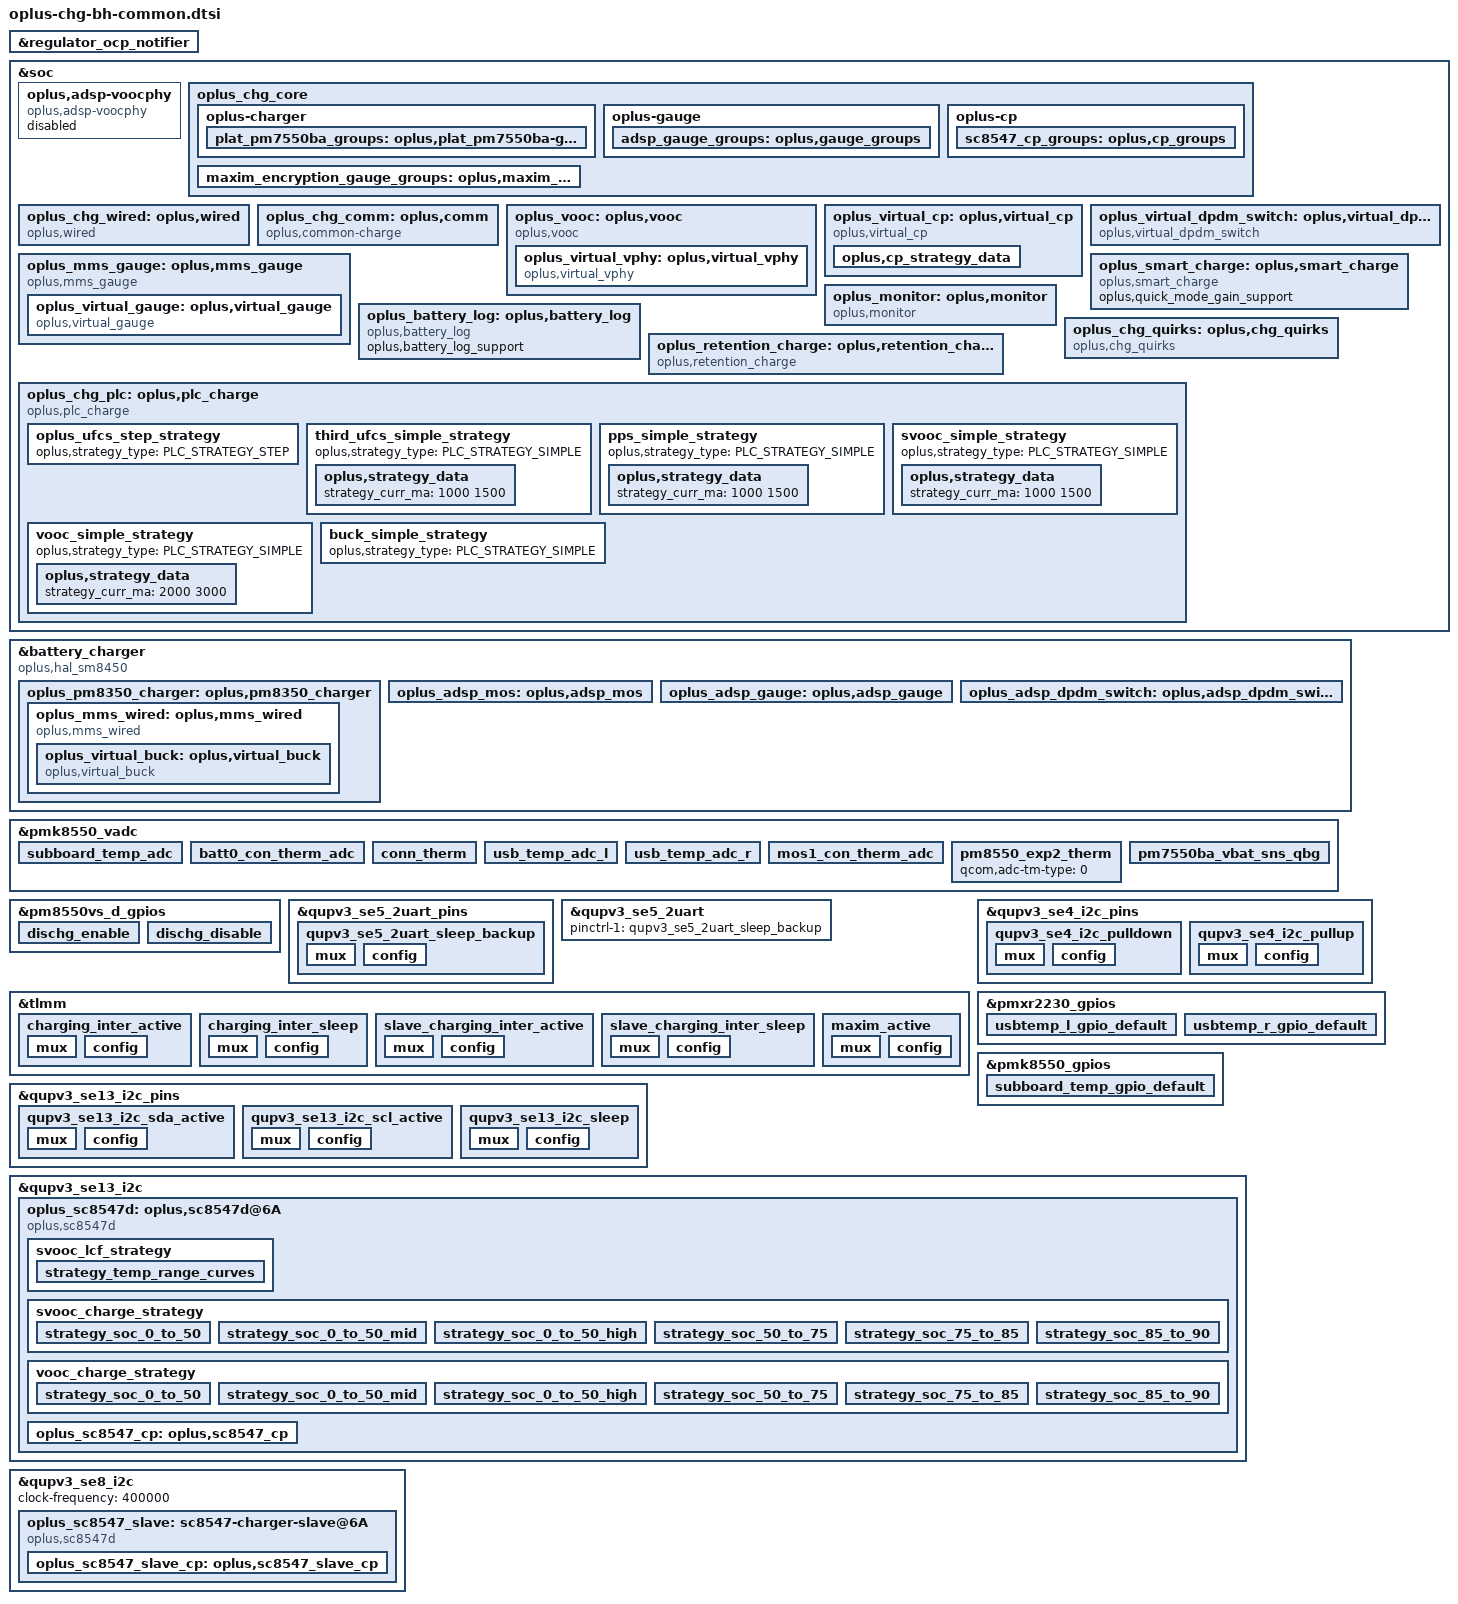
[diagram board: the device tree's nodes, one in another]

&regulator_ocp_notifier {
	periph-1cb-supply = <0>;
	periph-1cc-supply = <0>;
	periph-1cd-supply = <0>;
	periph-4c1-supply = <0>;
	periph-4c3-supply = <0>;
};

&soc {
	oplus,adsp-voocphy {
		status = "disabled";
		compatible = "oplus,adsp-voocphy";
	};

	oplus_chg_core {
		oplus,chg_framework_v2;
		oplus,smart_charging_screenoff;
		oplus,chg_spec_version = <OPLUS_CHG_SPEC_VER_V3P7>;
		oplus,common-charge-icl-support;

		oplus-charger {
			plat_pm7550ba_groups: oplus,plat_pm7550ba-groups {
				functions = <
					OPLUS_IC_FUNC_INIT
					OPLUS_IC_FUNC_EXIT
					OPLUS_IC_FUNC_REG_DUMP
					OPLUS_IC_FUNC_SMT_TEST
					OPLUS_IC_FUNC_BUCK_INPUT_PRESENT
					OPLUS_IC_FUNC_BUCK_INPUT_SUSPEND
					OPLUS_IC_FUNC_BUCK_INPUT_IS_SUSPEND
					OPLUS_IC_FUNC_BUCK_OUTPUT_SUSPEND
					OPLUS_IC_FUNC_BUCK_OUTPUT_IS_SUSPEND
					OPLUS_IC_FUNC_BUCK_GET_CC_ORIENTATION
					OPLUS_IC_FUNC_BUCK_GET_CHARGER_TYPE
					OPLUS_IC_FUNC_BUCK_RERUN_BC12
					OPLUS_IC_FUNC_BUCK_QC_DETECT_ENABLE
					OPLUS_IC_FUNC_BUCK_SHIPMODE_ENABLE
					OPLUS_IC_FUNC_BUCK_SET_QC_CONFIG
					OPLUS_IC_FUNC_BUCK_SET_PD_CONFIG
					OPLUS_IC_FUNC_BACKUP_SOC
					OPLUS_IC_FUNC_GET_SHUTDOWN_SOC
					OPLUS_IC_FUNC_GET_TYPEC_MODE
					OPLUS_IC_FUNC_BUCK_SET_ICL
					OPLUS_IC_FUNC_BUCK_GET_ICL
					OPLUS_IC_FUNC_BUCK_SET_FCC
					OPLUS_IC_FUNC_BUCK_SET_FV
					OPLUS_IC_FUNC_BUCK_SET_ITERM
					OPLUS_IC_FUNC_BUCK_SET_RECHG_VOL
					OPLUS_IC_FUNC_BUCK_GET_INPUT_CURR
					OPLUS_IC_FUNC_BUCK_GET_INPUT_VOL
					OPLUS_IC_FUNC_GET_CHARGER_CYCLE
					OPLUS_IC_FUNC_OTG_BOOST_ENABLE
					OPLUS_IC_FUNC_BUCK_GET_VBUS_COLLAPSE_STATUS
					OPLUS_IC_FUNC_GET_OTG_ENABLE
					OPLUS_IC_FUNC_SET_OTG_SWITCH_STATUS
					OPLUS_IC_FUNC_GET_OTG_SWITCH_STATUS
					OPLUS_IC_FUNC_GET_OTG_ONLINE_STATUS
					OPLUS_IC_FUNC_BUCK_GET_HW_DETECT
					OPLUS_IC_FUNC_VOOCPHY_SET_MATCH_TEMP
					OPLUS_IC_FUNC_IS_OPLUS_SVID
					OPLUS_IC_FUNC_BUCK_GET_USB_BTB_TEMP
					OPLUS_IC_FUNC_BUCK_GET_BATT_BTB_TEMP
					OPLUS_IC_FUNC_SET_TYPEC_MODE
					OPLUS_IC_FUNC_GET_TYPEC_ROLE
					OPLUS_IC_FUNC_BUCK_GET_USB_AICL_ENHANCE
					OPLUS_IC_FUNC_BUCK_SET_AICL_POINT
				>;
				virqs = <
					OPLUS_IC_VIRQ_ERR
					OPLUS_IC_VIRQ_CC_DETECT
					OPLUS_IC_VIRQ_PLUGIN
					OPLUS_IC_VIRQ_CC_CHANGED
					OPLUS_IC_VIRQ_CHG_TYPE_CHANGE
					OPLUS_IC_VIRQ_SVID
					OPLUS_IC_VIRQ_OTG_ENABLE
				>;
			};
		};

		oplus-gauge {
			adsp_gauge_groups: oplus,gauge_groups {
				functions = <
					OPLUS_IC_FUNC_INIT
					OPLUS_IC_FUNC_EXIT
					OPLUS_IC_FUNC_REG_DUMP
					OPLUS_IC_FUNC_SMT_TEST
					OPLUS_IC_FUNC_GAUGE_GET_BATT_VOL
					OPLUS_IC_FUNC_GAUGE_GET_BATT_MAX
					OPLUS_IC_FUNC_GAUGE_GET_BATT_MIN
					OPLUS_IC_FUNC_GAUGE_GET_BATT_CURR
					OPLUS_IC_FUNC_GAUGE_GET_BATT_TEMP
					OPLUS_IC_FUNC_GAUGE_GET_BATT_SOC
					OPLUS_IC_FUNC_GAUGE_GET_BATT_FCC
					OPLUS_IC_FUNC_GAUGE_GET_BATT_CC
					OPLUS_IC_FUNC_GAUGE_GET_BATT_RM
					OPLUS_IC_FUNC_GAUGE_GET_BATT_SOH
					OPLUS_IC_FUNC_GAUGE_GET_BATT_HMAC
					OPLUS_IC_FUNC_GAUGE_SET_BATT_FULL
					OPLUS_IC_FUNC_GAUGE_UPDATE_DOD0
					OPLUS_IC_FUNC_GAUGE_UPDATE_SOC_SMOOTH
					OPLUS_IC_FUNC_GAUGE_GET_CB_STATUS
					OPLUS_IC_FUNC_GAUGE_GET_BATT_NUM
					OPLUS_IC_FUNC_GAUGE_GET_DEVICE_TYPE
					OPLUS_IC_FUNC_GAUGE_GET_DEVICE_TYPE_FOR_VOOC
					OPLUS_IC_FUNC_GAUGE_GET_BATT_FCC
					OPLUS_IC_FUNC_GAUGE_UPDATE
					OPLUS_IC_FUNC_GAUGE_IS_SUSPEND
					OPLUS_IC_FUNC_GAUGE_GET_SUBBOARD_TEMP
					OPLUS_IC_FUNC_GAUGE_GET_BCC_PARMS
					OPLUS_IC_FUNC_GAUGE_GET_DEVICE_TYPE_FOR_BCC
					OPLUS_IC_FUNC_GAUGE_GET_DOD0
					OPLUS_IC_FUNC_GAUGE_GET_DOD0_PASSED_Q
					OPLUS_IC_FUNC_GAUGE_GET_QMAX
					OPLUS_IC_FUNC_GAUGE_GET_QMAX_PASSED_Q
					OPLUS_IC_FUNC_GAUGE_GET_DEC_FG_TYPE
					OPLUS_IC_FUNC_GAUGE_GET_DEC_CV_SOH
					OPLUS_IC_FUNC_GAUGE_SET_VCT
					OPLUS_IC_FUNC_GAUGE_GET_VCT
				>;
				virqs = <
					OPLUS_IC_VIRQ_ERR
					OPLUS_IC_VIRQ_OFFLINE
					OPLUS_IC_VIRQ_RESUME
				>;
			};
		};

		oplus-cp {
			sc8547_cp_groups: oplus,cp_groups {
				functions = <
					OPLUS_IC_FUNC_INIT
					OPLUS_IC_FUNC_EXIT
					OPLUS_IC_FUNC_REG_DUMP
					OPLUS_IC_FUNC_SMT_TEST
					OPLUS_IC_FUNC_CP_ENABLE
					OPLUS_IC_FUNC_CP_HW_INTI
					OPLUS_IC_FUNC_CP_SET_WORK_MODE
					OPLUS_IC_FUNC_CP_GET_WORK_MODE
					OPLUS_IC_FUNC_CP_CHECK_WORK_MODE_SUPPORT
					OPLUS_IC_FUNC_CP_SET_IIN
					OPLUS_IC_FUNC_CP_GET_VIN
					OPLUS_IC_FUNC_CP_GET_IIN
					OPLUS_IC_FUNC_CP_GET_VOUT
					OPLUS_IC_FUNC_CP_GET_IOUT
					OPLUS_IC_FUNC_CP_GET_VAC
					OPLUS_IC_FUNC_CP_SET_WORK_START
					OPLUS_IC_FUNC_CP_GET_WORK_STATUS
					OPLUS_IC_FUNC_CP_SET_ADC_ENABLE
					OPLUS_IC_FUNC_CP_WATCHDOG_ENABLE
					OPLUS_IC_FUNC_CP_SET_UCP_DISABLE
					OPLUS_IC_FUNC_CP_GET_IIN_MAX
					OPLUS_IC_FUNC_CP_WATCHDOG_RESET
				>;
				virqs = <
					OPLUS_IC_VIRQ_ERR
					OPLUS_IC_VIRQ_ONLINE
					OPLUS_IC_VIRQ_OFFLINE
				>;
			};
		};

		maxim_encryption_gauge_groups: oplus,maxim_encryption_gauge_groups {
			functions = <
				OPLUS_IC_FUNC_INIT
				OPLUS_IC_FUNC_EXIT
				OPLUS_IC_FUNC_GAUGE_GET_BATT_AUTH
			>;
			virqs = <
				OPLUS_IC_VIRQ_ERR
			>;
		};
	};

	oplus_chg_wired: oplus,wired {
		compatible = "oplus,wired";
		oplus,vooc-support;

		oplus_spec,vbatt_pdqc_to_9v_thr = <5000>;
		oplus_spec,pd-iclmax-ma = <1500>;
		oplus_spec,qc-iclmax-ma = <1500>;
		oplus_spec,non-standard-ibatmax-ma = <500>;
		oplus_spec,input-power-mw = <
			2500		/* OPLUS_WIRED_CHG_MODE_UNKNOWN */
			2500		/* OPLUS_WIRED_CHG_MODE_SDP */
			7500		/* OPLUS_WIRED_CHG_MODE_CDP */
			10000		/* OPLUS_WIRED_CHG_MODE_DCP */
			30000		/* OPLUS_WIRED_CHG_MODE_VOOC */
			13500		/* OPLUS_WIRED_CHG_MODE_QC */
			13500		/* OPLUS_WIRED_CHG_MODE_PD */
		>;
		oplus_spec,led_on-fccmax-ma = <0 1340 4000 4000 4000 4000 4000 1000 0>;
		oplus_spec,fccmax-ma-lv = <
			0 1705 2200 2200 2200 2200 2200 2200 0	/* OPLUS_WIRED_CHG_MODE_UNKNOWN */
			0 600  600  600  600  600  600  600  0	/* OPLUS_WIRED_CHG_MODE_SDP */
			0 1600 1600 1600 1600 1600 1600 1600 0	/* OPLUS_WIRED_CHG_MODE_CDP */
			0 1705 2200 2200 2200 2200 2200 2200 0	/* OPLUS_WIRED_CHG_MODE_DCP */
			0 1340 3600 3600 3600 3600 3600 2948 0	/* OPLUS_WIRED_CHG_MODE_VOOC */
			0 1705 3300 3300 3300 3300 3300 3300 0	/* OPLUS_WIRED_CHG_MODE_QC */
			0 1705 3300 3300 3300 3300 3300 3300 0	/* OPLUS_WIRED_CHG_MODE_PD */
		>;
		oplus_spec,fccmax-ma-hv = <
			0 1705 2200 2200 2200 2200 2200 2200 0	/* OPLUS_WIRED_CHG_MODE_UNKNOWN */
			0 600  600  600  600  600  600  600  0	/* OPLUS_WIRED_CHG_MODE_SDP */
			0 1600 1600 1600 1600 1600 1600 1600 0	/* OPLUS_WIRED_CHG_MODE_CDP */
			0 1705 2200 2200 2200 2200 2200 2200 0	/* OPLUS_WIRED_CHG_MODE_DCP */
			0 1340 3600 3600 3600 3600 3600 2948 0	/* OPLUS_WIRED_CHG_MODE_VOOC */
			0 1705 3300 3300 3300 3300 3300 3300 0	/* OPLUS_WIRED_CHG_MODE_QC */
			0 1705 3300 3300 3300 3300 3300 3300 0	/* OPLUS_WIRED_CHG_MODE_PD */
		>;

		oplus_spec,cool_down_pdqc_vol_mv = <5000 5000 5000 9000>;
		oplus_spec,cool_down_pdqc_curr_ma = <1200 1500 2000 1500>;
		oplus_spec,cool_down_vooc_curr_ma = <1200 1500 2000 2500 3000 3000>;
		oplus_spec,cool_down_normal_curr_ma = <1200 1500 2000>;

		oplus_spec,vbus_ov_thr_mv = <11000 11000>;
		oplus_spec,vbus_uv_thr_mv = <4300 4300>;

		/* first data is strategy used temp type */
		oplus,vooc_strategy_name = "cgcl";
		oplus,vooc_strategy_data = <OPLUS_STRATEGY_USE_BATT_TEMP
					    0   380 6000 1 0
					    370 410 5000 2 0
					    400 420 4000 3 1
					    410 440 2000 3 2>;
	};

	oplus_chg_comm: oplus,comm {
		compatible = "oplus,common-charge";
		oplus_spec,dec_step = <20>;
		oplus_spec,dec-vol-cc-full-thr = <0 400 600 800 1000 1200>;
		oplus_spec,dec-vol-fv-full-mv = <0 20 20 40 40 40>;
		oplus_spec,batt-them-thr = <(-100) 0 50 120 160 350 450 530>;
		oplus_spec,iterm-ma = <351>;
		oplus_spec,removed_bat_decidegc = <390>; /*-39 degree*/
		oplus_spec,fv-mv = <4490 4490 4490 4490 4490 4490 4470 4130 4130>;
		oplus_spec,sw-fv-mv = <4440 4440 4440 4440 4440 4440 4420 4080 4080>;
		oplus_spec,hw-fv-inc-mv = <0 18 18 18 18 18 18 18 0>;
		oplus_spec,sw-over-fv-mv = <4500 4500 4500 4500 4500 4500 4480 4140 4140>;
		oplus_spec,sw-over-fv-dec-mv = <8>;
		oplus_spec,non-standard-sw-fv-mv = <3930>;
		oplus_spec,non-standard-fv-mv = <3980>;
		oplus_spec,non-standard-hw-fv-inc-mv = <18>;
		oplus_spec,non-standard-sw-over-fv-mv = <3990>;
		oplus_spec,non-standard-vbatdet-mv = <3680>;
		oplus_spec,wired-vbatdet-mv = <0 4190 4290 4390 4390 4390 4370 4030 0>;
		oplus_spec,fcc-gear-thr-mv = <4180>;
		oplus_spec,fcc-gear-shake-mv = <500 500 500 400 300 200 200 200 200>;
		oplus_spec,vbatt-ov-thr-mv = <4600>;

		oplus_spec,full_pre_ffc_judge;
		oplus_spec,full-pre-ffc-mv = <4485>;
		oplus_spec,ffc-temp-thr = <120 210 350 440>;
		oplus_spec,wired-ffc-step-max = <2>;
		oplus_spec,wired-ffc-fv-mv = <4630 4630>;

		oplus_spec,wired-ffc-fv-cutoff-mv = <4560 4525 4504
							4530 4505 4487>;
		oplus_spec,wired-ffc-fcc-ma = <1500 1500 1500
					       1500  1000  1000>;
		oplus_spec,wired-ffc-fcc-cutoff-ma = <1300 1300 1300
						      900 900 900>;

		oplus_spec,vbat_uv_thr_mv = <3300>;
		oplus_spec,vbat_charging_uv_thr_mv = <3200>;

		/*If use subboard NTC as battery temp, config it as 20, otherwise 0 */
		oplus_spec,tbatt_power_off_cali_temp = <0>;
		oplus,vooc_show_ui_soc_decimal;
		oplus_spec,poweroff_high_batt_temp = <720>;
		oplus_spec,poweroff_emergency_batt_temp = <770>;
		oplus,ui_soc_decimal_speedmin = <20>;

		oplus,gauge_stuck_jump_support;
		oplus,gauge_stuck_threshold = <15>;
		oplus,gauge_stuck_time = <50>;

		oplus,smooth_switch;
		oplus,reserve_chg_soc = <2>;
	};

	oplus_vooc: oplus,vooc {
		compatible = "oplus,vooc";
		oplus,vooc_ic = <&oplus_virtual_vphy>;

		oplus_spec,vooc_soc_range = <50 75 85>;
		oplus_spec,vooc_temp_range = <50 120 180 350 450>;

		oplus,vooc_data_width = <7>;
		oplus,vooc_curr_max = <CP_CURR_LIMIT_7BIT_15_0A>;  /* 80W: 11V 7.3A(IBUS *2) */
		oplus,vooc_project = <7>;  /* 80W, 11V 7.3A */
		oplus,vooc_curr_table_type = <VOOC_CP_CURR_TABLE>;
		oplus,vooc_power_max_w = <80>;
		oplus,voocphy_support = <3>; /* AP_DUAL_CP_VOOCPHY */
		oplus,support_fake_vooc_check;
		oplus,subboard_ntc_abnormal_current = <4000>;

		oplus,abnormal_adapter_current = <CP_CURR_LIMIT_7BIT_15_0A CP_CURR_LIMIT_7BIT_15_0A
						CP_CURR_LIMIT_7BIT_10_0A CP_CURR_LIMIT_7BIT_10_0A
						CP_CURR_LIMIT_7BIT_8_0A CP_CURR_LIMIT_7BIT_8_0A
						CP_CURR_LIMIT_7BIT_6_0A CP_CURR_LIMIT_7BIT_6_0A
						CP_CURR_LIMIT_7BIT_4_0A CP_CURR_LIMIT_7BIT_4_0A>;

		oplus,abnormal_over_80w_adapter_current = <CP_CURR_LIMIT_7BIT_15_0A CP_CURR_LIMIT_7BIT_15_0A
						CP_CURR_LIMIT_7BIT_14_0A CP_CURR_LIMIT_7BIT_14_0A
						CP_CURR_LIMIT_7BIT_12_0A CP_CURR_LIMIT_7BIT_12_0A
						CP_CURR_LIMIT_7BIT_10_0A CP_CURR_LIMIT_7BIT_10_0A
						CP_CURR_LIMIT_7BIT_8_0A  CP_CURR_LIMIT_7BIT_8_0A
						CP_CURR_LIMIT_7BIT_6_0A  CP_CURR_LIMIT_7BIT_6_0A
						CP_CURR_LIMIT_7BIT_4_0A CP_CURR_LIMIT_7BIT_4_0A>;

		/* first data is strategy used temp type */
		oplus,general_strategy_name = "cgcl";
		oplus,general_strategy_data = < OPLUS_STRATEGY_USE_SHELL_TEMP
						0   370 CP_CURR_LIMIT_7BIT_15_0A 1 0
						360 390 CP_CURR_LIMIT_7BIT_10_0A 2 0
						380 410 CP_CURR_LIMIT_7BIT_8_0A  3 1
						400 420 CP_CURR_LIMIT_7BIT_6_0A  4 2
						410 440 CP_CURR_LIMIT_7BIT_4_0A  4 3>;
		oplus,plc_strategy-data = <&buck_simple_strategy &svooc_simple_strategy &vooc_simple_strategy>;
		oplus,plc_strategy-names = "default", "svooc", "vooc";
		oplus_virtual_vphy: oplus,virtual_vphy {
			compatible = "oplus,virtual_vphy";
			oplus,vphy_ic = <&oplus_sc8547d>;
			oplus,dpdm_switch_ic = <&oplus_virtual_dpdm_switch>;

			oplus,ic_type = <OPLUS_CHG_IC_VIRTUAL_VPHY>;
			oplus,ic_index = <0>;
		};
	};

	oplus_virtual_cp: oplus,virtual_cp {
		compatible = "oplus,virtual_cp";

		oplus,ic_type = <OPLUS_CHG_IC_VIRTUAL_CP>;
		oplus,ic_index = <0>;

		oplus,cp_ic = <&oplus_sc8547_cp &oplus_sc8547_slave_cp>;
		oplus,input_curr_max_ma = <4000 4000>;

		oplus,cp_ic_connect = <OPLUS_CHG_IC_CONNECT_PARALLEL>;
		oplus,main_cp = <0>;

		oplus,reg_proc_node;
		oplus,cp_strategy = <CP_STRAT_OPEN_BY_CURR>;
		oplus,cp_strategy_data {
			oplus,cp_open_curr_thr_ma = <0 1900>;
			oplus,cp_close_curr_thr_ma = <0 1600>;
		};
	};

	oplus_virtual_dpdm_switch: oplus,virtual_dpdm_switch {
		compatible = "oplus,virtual_dpdm_switch";
		oplus,ic_type = <OPLUS_CHG_IC_MISC>;
		oplus,ic_index = <0>;
		oplus,use_audio_switch;
	};

	oplus_mms_gauge: oplus,mms_gauge {
		compatible = "oplus,mms_gauge";
		oplus,gauge_ic = <&oplus_virtual_gauge>;
		oplus,voocphy_ic = <&oplus_virtual_vphy>;
		oplus,topic-update-interval = <5000>;
		oplus,support_subboard_ntc;

		oplus_virtual_gauge: oplus,virtual_gauge {
			compatible = "oplus,virtual_gauge";
			oplus,gauge_ic = <&oplus_adsp_gauge &maxim_encryption_gauge>;
			oplus,gauge_ic_index = <0 1>;
			oplus,gauge_ic_func_group =  <&adsp_gauge_groups &maxim_encryption_gauge_groups>;
			oplus,batt_capacity_mah = <7000>;
			oplus,ic_type = <OPLUS_CHG_IC_VIRTUAL_GAUGE>;
			oplus,ic_index = <0>;
		};
	};

	oplus_smart_charge: oplus,smart_charge {
		compatible = "oplus,smart_charge";
		oplus,quick_mode_gain_support;
	};


	oplus_battery_log: oplus,battery_log {
		compatible = "oplus,battery_log";
		oplus,battery_log_support;
	};

	oplus_monitor: oplus,monitor {
		compatible = "oplus,monitor";
		oplus,topic-update-interval = <60000>;
		track,fast_chg_break_t_thd = <1400>;
		track,general_chg_break_t_thd = <300>;
		track,voocphy_type = <2>;
		track,wired_max_power = <80000>;
		track,wired_fast_chg_scheme = <1>;
	};

	oplus_chg_quirks: oplus,chg_quirks {
		compatible = "oplus,chg_quirks";
	};
	oplus_retention_charge: oplus,retention_charge {
		compatible = "oplus,retention_charge";
		oplus,topic-update-interval = <5000>;
		oplus,support_retention_name = "oplus_retention_quirks";
	};
};

&soc {
	oplus_chg_plc: oplus,plc_charge {
		compatible = "oplus,plc_charge";
		oplus,plc_soc = <90>;
		oplus,plc_strategy-data = <&buck_simple_strategy>;
		oplus,plc_strategy-names = "default";

		oplus_ufcs_step_strategy: oplus_ufcs_step_strategy {
			oplus,strategy_type = <PLC_STRATEGY_STEP>;
		};

		third_ufcs_simple_strategy: third_ufcs_simple_strategy {
			oplus,strategy_type = <PLC_STRATEGY_SIMPLE>;
			oplus,strategy_data {
				strategy_curr_ma = <1000 1500>;
			};
		};

		pps_simple_strategy: pps_simple_strategy {
			oplus,strategy_type = <PLC_STRATEGY_SIMPLE>;
			oplus,strategy_data {
				strategy_curr_ma = <1000 1500>;
			};
		};

		svooc_simple_strategy: svooc_simple_strategy {
			oplus,strategy_type = <PLC_STRATEGY_SIMPLE>;
			oplus,strategy_data {
				strategy_curr_ma = <1000 1500>;
			};
		};

		vooc_simple_strategy: vooc_simple_strategy {
			oplus,strategy_type = <PLC_STRATEGY_SIMPLE>;
			oplus,strategy_data {
				strategy_curr_ma = <2000 3000>;
			};
		};


		buck_simple_strategy: buck_simple_strategy {
			oplus,strategy_type = <PLC_STRATEGY_SIMPLE>;
		};
	};
};

&battery_charger {
	compatible = "oplus,hal_sm8450";

	qcom,pmic_ftm_vph = "/sys/bus/spmi/drivers/pmic-spmi/0-00/c42d000.qcom,spmi:qcom,pmk8550@0:vadc@9000/iio:device0/in_voltage_pm7550ba_vph_pwr_input";
	qcom,pmic_ftm_vbat = "/sys/bus/spmi/drivers/pmic-spmi/0-00/c42d000.qcom,spmi:qcom,pmk8550@0:vadc@9000/iio:device0/in_voltage_pm7550ba_vbat_sns_qbg_input";

	pinctrl-names = "subboard_temp_gpio_default";
	pinctrl-0 = <&subboard_temp_gpio_default>;

	//oplus,voocphy_bidirect_cp_support;
	oplus,chg_ops = "plat-pmic";
	oplus,otg_boost_src = <0>; /* 0:plat_pmic 1:external */
	oplus,batt_num = <1>;
	oplus,otg_scheme = <0>; /* 0:cid 1:ccdetect_gpio 2:switch */
	oplus,usb_aicl_enhance;

	/* QCOM QBG full param, depend on adapter type and temp_region */
	oplus,batt_full_method_new;
	oplus,batt_full_temp = <(-100) 120 210 440>;
	oplus,batt_full_para = <1351 1351 1351 1351      /* normal pd qc */
				1351 2751 2951 1351      /* svooc */
				1351 2751 2951 1351      /* oplus ufcs */
				1351 2751 2751 1351      /* oplus pps */
				1351 1351 1351 1351      /* third ufcs */
				1351 1351 1351 1351      /* third pps */
				1351 1351 1451 1351>;    /* ffc */

	oplus,ic_type = <OPLUS_CHG_IC_BUCK>;
	oplus,ic_index = <0>;
	io-channels = <&pmk8550_vadc PMK8550_ADC5_GEN3_AMUX_THM3_GPIO2_100K_PU>,
		      <&pmk8550_vadc PMK8550_ADC5_GEN3_AMUX_THM2_GPIO1_100K_PU>,
		      <&pmk8550_vadc PM7550BA_ADC5_GEN3_AMUX_THM6_GPIO6_100K_PU>,
		      <&pmk8550_vadc PM7550BA_ADC5_GEN3_AMUX_THM4_USB_THERM_100K_PU>;

	io-channel-names = "mos1_con_therm_adc",
			   "subboard_temp_adc",
			   "batt0_con_therm_adc",
			   "conn_therm";

	oplus_pm8350_charger: oplus,pm8350_charger {
		oplus,ic_type = <OPLUS_CHG_IC_BUCK>;
		oplus,ic_index = <0>;

		oplus_mms_wired: oplus,mms_wired {
			compatible = "oplus,mms_wired";
			oplus,buck_ic = <&oplus_virtual_buck>;
			oplus,voocphy_ic = <&oplus_virtual_vphy>;
			oplus,usbtemp_batttemp_gap = <10>;
			oplus,adc_info_name = "855";
			oplus,topic-update-interval = <5000>;

			high-temp-scheme;
			oplus,support_usbtemp_protect_v2;
			oplus_spec,usbtemp_batt_temp_low = <50>;
			oplus_spec,usbtemp_batt_temp_high = <50>;
			oplus_spec,usbtemp_batt_temp_over_hot = <60>;
			oplus_spec,usbtemp_ntc_temp_low = <57>;
			oplus_spec,usbtemp_ntc_temp_high = <69>;
			oplus_spec,usbtemp_temp_gap_low_with_batt_temp = <7>;
			oplus_spec,usbtemp_temp_gap_with_batt_temp_in_over_hot = <15>;
			oplus_spec,usbtemp_temp_gap_high_with_batt_temp = <12>;
			oplus_spec,usbtemp_temp_gap_low_without_batt_temp = <12>;
			oplus_spec,usbtemp_temp_gap_high_without_batt_temp = <24>;
			oplus_spec,usbtemp_rise_fast_temp_low = <3>;
			oplus_spec,usbtemp_rise_fast_temp_high = <3>;
			oplus_spec,usbtemp_rise_fast_temp_count_low = <30>;
			oplus_spec,usbtemp_rise_fast_temp_count_high = <20>;
			oplus_spec,usbtemp_cool_down_ntc_low = <54>;
			oplus_spec,usbtemp_cool_down_ntc_high = <65>;
			oplus_spec,usbtemp_cool_down_gap_low = <12>;
			oplus_spec,usbtemp_cool_down_gap_high = <20>;
			oplus_spec,usbtemp_cool_down_recover_ntc_low = <48>;
			oplus_spec,usbtemp_cool_down_recover_ntc_high = <60>;
			oplus_spec,usbtemp_cool_down_recover_gap_low = <6>;
			oplus_spec,usbtemp_cool_down_recover_gap_high = <15>;

		oplus_virtual_buck: oplus,virtual_buck {
			compatible = "oplus,virtual_buck";
			oplus,buck_ic = <&oplus_pm8350_charger>;
			oplus,buck_ic_index = <0>;
			oplus,buck_ic_connect = <OPLUS_CHG_IC_CONNECT_PARALLEL>;
			oplus,main_charger = <0>;
			oplus,buck_ic_current_ratio = <100>;
			oplus,buck_ic_func_group = <&plat_pm7550ba_groups>;

			oplus,ic_type = <OPLUS_CHG_IC_VIRTUAL_BUCK>;
			oplus,ic_index = <0>;

			oplus,uart_tx-gpio = <&tlmm 22 0x00>;
			oplus,uart_rx-gpio = <&tlmm 23 0x00>;

			oplus,dischg-gpio = <&pm8550vs_d_gpios 4 0x00>;
			//oplus,ship-gpio = <&tlmm 146 0x00>;
			pinctrl-names = "usbtemp_l_gpio_default", "usbtemp_r_gpio_default", /* TODO */
					"dischg_enable", "dischg_disable";
			pinctrl-0 = <&usbtemp_l_gpio_default>;
			pinctrl-1 = <&usbtemp_r_gpio_default>;
			pinctrl-2 = <&dischg_enable>;
			pinctrl-3 = <&dischg_disable>;

			io-channels = <&pmk8550_vadc PMXR2230_ADC5_GEN3_AMUX1_GPIO3_100K_PU>,
				      <&pmk8550_vadc PMXR2230_ADC5_GEN3_AMUX2_GPIO4_100K_PU>;
			io-channel-names = "usb_temp_adc_l",
					   "usb_temp_adc_r";
			};
		};
	};

	oplus_adsp_mos: oplus,adsp_mos {
		oplus,ic_type = <OPLUS_CHG_IC_CP>;
		oplus,ic_index = <0>;
	};

	oplus_adsp_gauge: oplus,adsp_gauge {
		oplus,ic_type = <OPLUS_CHG_IC_GAUGE>;
		oplus,ic_index = <0>;
	};

	oplus_adsp_dpdm_switch: oplus,adsp_dpdm_switch {
		oplus,ic_type = <OPLUS_CHG_IC_MISC>;
		oplus,ic_index = <0>;
	};
};

&pmk8550_vadc {
	subboard_temp_adc {
		reg = <PMK8550_ADC5_GEN3_AMUX_THM2_GPIO1_100K_PU>;
		label = "subboard_temp_adc";
		qcom,pre-scaling = <1 1>;
		qcom,ratiometric;
		qcom,hw-settle-time = <200>;
		qcom,scale-fn-type = <OPLUS_ADC_SCALE_HW_CALIB_DEFAULT>;
	};

	batt0_con_therm_adc {
		reg = <PM7550BA_ADC5_GEN3_AMUX_THM6_GPIO6_100K_PU>;
                label = "batt0_con_therm_adc";
                qcom,pre-scaling = <1 1>;
                qcom,ratiometric;
                qcom,hw-settle-time = <200>;
                qcom,scale-fn-type = <OPLUS_ADC_SCALE_HW_CALIB_DEFAULT>;
	};

	conn_therm {
		reg = <PM7550BA_ADC5_GEN3_AMUX_THM4_USB_THERM_100K_PU>;
                label = "conn_therm";
                qcom,pre-scaling = <1 1>;
                qcom,ratiometric;
                qcom,hw-settle-time = <200>;
                qcom,scale-fn-type = <OPLUS_ADC_SCALE_HW_CALIB_DEFAULT>;
	};

	usb_temp_adc_l {
		reg = <PMXR2230_ADC5_GEN3_AMUX1_GPIO3_100K_PU>;
                label = "usb_temp_adc_l";
                qcom,pre-scaling = <1 1>;
                qcom,ratiometric;
                qcom,hw-settle-time = <200>;
                qcom,scale-fn-type = <OPLUS_ADC_SCALE_HW_CALIB_DEFAULT>;
	};

	usb_temp_adc_r{
		reg = <PMXR2230_ADC5_GEN3_AMUX2_GPIO4_100K_PU>;
                label = "usb_supplementary_temp_adc ";
                qcom,pre-scaling = <1 1>;
                qcom,ratiometric;
                qcom,hw-settle-time = <200>;
                qcom,scale-fn-type = <OPLUS_ADC_SCALE_HW_CALIB_DEFAULT>;
	};

	/* TODO: the mos themperature is used by which? */
	mos1_con_therm_adc {
		reg = <PMK8550_ADC5_GEN3_AMUX_THM3_GPIO2_100K_PU>;
                label = "mos1_con_therm_adc";
                qcom,pre-scaling = <1 1>;
                qcom,ratiometric;
                qcom,hw-settle-time = <200>;
                qcom,scale-fn-type = <OPLUS_ADC_SCALE_HW_CALIB_DEFAULT>;
	};

	/* disable the pm8550_exp2_therm to fix the usb_temp_adc init failed! */
	pm8550_exp2_therm {
		qcom,adc-tm-type = <0>;
	};

	pm7550ba_vbat_sns_qbg {
		reg = <PM7550BA_ADC5_GEN3_VBAT_SNS_QBG>;
		label = "pm7550ba_vbat_sns_qbg";
		qcom,pre-scaling = <1 3>;
	};
};

&pm8550vs_d_gpios {
	dischg_enable: dischg_enable {
		pins = "gpio4";
		function = "normal";
		bias-disable;
		power-source = <0>;
		output-high;
		qcom,drive-strength = <2>;
	};

	dischg_disable: dischg_disable {
		pins = "gpio4";
		function = "normal";
		bias-disable;
		power-source = <0>;
		output-low;
		qcom,drive-strength = <2>;
	};
};

&qupv3_se5_2uart_pins {
	qupv3_se5_2uart_sleep_backup:qupv3_se5_2uart_sleep_backup {
 		mux {
			pins = "gpio22", "gpio23";
			function = "gpio";
		};

		config {
			pins = "gpio22", "gpio23";
			drive-strength = <2>;
			bias-disable;
			input-enable;
		};
	};
};

&qupv3_se5_2uart {
	pinctrl-1 = <&qupv3_se5_2uart_sleep_backup>;
	status = "ok";
};

&tlmm {
	charging_inter_active: charging_inter_active {
		mux {
			pins = "gpio51";
			function = "gpio";
		};
		config {
			pins = "gpio51";
			bias-pull-up; /* NO pull */
			drive-strength = <2>; /* 2 MA */
			input-enable;
		};
	};

	charging_inter_sleep: charging_inter_sleep {
		mux {
			pins = "gpio51"; /* sc8547d_INT*/
			function = "gpio";
		};
		config {
			pins = "gpio51";
			bias-pull-up;
			drive-strength = <2>; /* 2 MA */
			input-enable;
		};
	};

	slave_charging_inter_active: slave_charging_inter_active {
		mux {
			pins = "gpio128";
			function = "gpio";
		};
		config {
			pins = "gpio128";
			bias-pull-up;
			drive-strength = <2>;
			input-enable;
		};
	};

	slave_charging_inter_sleep: slave_charging_inter_sleep {
		mux {
			pins = "gpio128";
			function = "gpio";
		};
		config {
			pins = "gpio128";
			bias-pull-up;
			drive-strength = <2>;
			input-enable;
		};
	};

	maxim_active: maxim_active {
		mux {
			pins = "gpio146";
			function = "gpio";
		};

		config {
			pins = "gpio146";
			bias-pull-up;
			drive-strength = <16>;
		};
	};
};

&qupv3_se4_i2c_pins {
	qupv3_se4_i2c_pulldown: qupv3_se4_i2c_pulldown {
		mux {
			pins = "gpio16", "gpio17";
			function = "gpio";
		};

		config {
			pins = "gpio16", "gpio17";
			drive-strength = <2>;
			bias-pull-down;
			output-low;
		};
	};

	qupv3_se4_i2c_pullup: qupv3_se4_i2c_pullup {
		mux {
			pins = "gpio16", "gpio17";
			function = "gpio";
		};

		config {
			pins = "gpio16", "gpio17";
			drive-strength = <2>;
			bias-pull-up;
			input-enable;
		};
	};
};

&qupv3_se13_i2c_pins {
	qupv3_se13_i2c_sda_active: qupv3_se13_i2c_sda_active {
		mux {
			pins = "gpio52";
			function = "qup1_se5_l0";
		};

		config {
			pins = "gpio52";
			drive-strength = <2>;
			bias-pull-up;
			qcom,i2c_pull; /* 2.2k Pull up */
		};
	};

	qupv3_se13_i2c_scl_active: qupv3_se13_i2c_scl_active {
		mux {
			pins = "gpio53";
			function = "qup1_se5_l1";
		};

		config {
			pins = "gpio53";
			drive-strength = <2>;
			bias-pull-up;
			qcom,i2c_pull; /* 2.2k Pull up */
		};
	};

	qupv3_se13_i2c_sleep: qupv3_se13_i2c_sleep {
		mux {
			pins = "gpio52", "gpio53";
			function = "gpio";
		};

		config {
			pins = "gpio52", "gpio53";
			drive-strength = <2>;
			bias-pull-up;
			qcom,i2c_pull; /* 2.2k Pull up */
		};
	};
};

&pmxr2230_gpios {
	usbtemp_l_gpio_default: usbtemp_l_gpio_default {
		pins = "gpio3"; //GPIO 3
		function = "normal"; //normal
		bias-high-impedance; //DISABLE GPIO3 for ADC
		bias-disable;
	};

	usbtemp_r_gpio_default: usbtemp_r_gpio_default {
		pins = "gpio4"; //GPIO 4
		function = "normal"; //normal
		bias-high-impedance; //DISABLE GPIO4 for ADC
		bias-disable;
	};
};

&pmk8550_gpios {
	subboard_temp_gpio_default: subboard_temp_gpio_default {
		pins = "gpio1"; /* GPIO 1 */
		function = "normal"; /* normal */
		bias-high-impedance; /* DISABLE GPIO1 for ADC*/
	};
};

&qupv3_se13_i2c {
	status = "okay";
	qcom,clk-freq-out = <400000>;
	qcom,request-cpu-qos;
	pinctrl-names = "default", "sleep";
	pinctrl-0 = <&qupv3_se13_i2c_sda_active>, <&qupv3_se13_i2c_scl_active>;
	pinctrl-1 = <&qupv3_se13_i2c_sleep>;

	oplus_sc8547d: oplus,sc8547d@6A {
		status = "okay";
		compatible = "oplus,sc8547d";
		reg = <0x6A>;

		ocp_reg = <0xe>;
		ovp_reg = <0x36>;
		vbus_ovp_reg = /bits/ 8 <0x5A>;

		oplus,use_vooc_phy;
		oplus,use_ufcs_phy;
		oplus,vac_support;
		oplus,always_otg_en;
		oplus,irq_gpio = <&tlmm 51 0x00>;
		pinctrl-names = "charging_inter_active", "charging_inter_sleep";
		pinctrl-0 = <&charging_inter_active>;
		pinctrl-1 = <&charging_inter_sleep>;

		oplus,ic_type = <OPLUS_CHG_IC_VPHY>;
		oplus,ic_index = <0>;
		oplus,vooc-version = <VOOC_VERSION_5_0>;

		oplus_spec,vooc_bad_volt = <3450 3400 3350 3300>;
		oplus_spec,vooc_bad_volt_suspend = <3450 3400 3350 3300>;
		oplus_spec,vooc_bad_volt_check_head_mask = /bits/ 8 <0x3>; /* VOOC 2.0/VOOC3.0 */
		oplus_spec,ap_control_allow;

		oplus_spec,voocphy_dual_cp_support;
		oplus_spec,slave_cp_enable_thr = <1400>;		//2000-100mA
		oplus_spec,slave_cp_disable_thr_high = <1100>;//1500+100mA
		oplus_spec,impedance_calculation_newmethod;
		oplus_spec,svooc_circuit_r_l = <0xa>;
		oplus_spec,svooc_circuit_r_h = <0x1>;
		oplus_spec,voocphy_current_default = <73>;

		oplus_spec,svooc_cool_down_current_limit = <146 20 20 24 30 34 40 44 50 54 60 64 70 74 80 90 100 110 146>;
		oplus_spec,vooc_cool_down_current_limit = <73 20 20 24 30 34 40 44 50 54 73>;

		oplus_spec,vooc_multistep_initial_batt_temp = <1000>;
		oplus_spec,vooc_little_cool_temp = <160>;
		oplus_spec,vooc_little_cool_high_temp = <210>;
		oplus_spec,vooc_cool_temp = <120>;
		oplus_spec,vooc_little_cold_temp = <50>;
		oplus_spec,vooc_normal_low_temp = <350>;
		oplus_spec,vooc_strategy_normal_current = <146>;
		oplus_spec,vooc_normal_to_little_cool_current = <100>;
		oplus_spec,vooc_over_high_temp = <510>;
		oplus_spec,vooc_low_temp = <0>;

		oplus_spec,vooc_high_temp = <500>;
		oplus_spec,vooc_low_soc = <0>;
		oplus_spec,vooc_high_soc = <90>;
		oplus_spec,vooc_normal_high_temp = <440>;
		oplus_spec,vooc_warm_vol_thr = <4000>;
		oplus_spec,vooc_warm_soc_thr = <55>;

		oplus_spec,vooc_strategy1_batt_high_temp0 = <385>;
		oplus_spec,vooc_strategy1_batt_high_temp1 = <395>;
		oplus_spec,vooc_strategy1_batt_high_temp2 = <420>;
		oplus_spec,vooc_strategy1_batt_low_temp2 = <410>;
		oplus_spec,vooc_strategy1_batt_low_temp1 = <385>;
		oplus_spec,vooc_strategy1_batt_low_temp0 = <375>;

		oplus_spec,vooc_strategy1_high_current0 = <80>;
		oplus_spec,vooc_strategy1_high_current1 = <60>;
		oplus_spec,vooc_strategy1_high_current2 = <40>;
		oplus_spec,vooc_strategy1_low_current2 = <60>;
		oplus_spec,vooc_strategy1_low_current1 = <80>;
		oplus_spec,vooc_strategy1_low_current0 = <146>;

		oplus_spec,vooc_strategy1_high_current0_vooc = <59>;
		oplus_spec,vooc_strategy1_high_current1_vooc = <59>;
		oplus_spec,vooc_strategy1_high_current2_vooc = <40>;
		oplus_spec,vooc_strategy1_low_current2_vooc = <59>;
		oplus_spec,vooc_strategy1_low_current1_vooc = <59>;
		oplus_spec,vooc_strategy1_low_current0_vooc = <59>;

		oplus_spec,voocphy_req_freq = <1804800 2400000 2400000 2630400>;
		oplus_spec,voocphy_freq_mincore = <1804800>;
		oplus_spec,voocphy_freq_midcore = <2400000>;
		oplus_spec,voocphy_freq_maxcore = <2630400>;
		oplus_spec,voocphy_current_change_timeout = <100>;
		oplus_spec,copycat_vooc_support;
		oplus_spec,copycat_vooc_accuracy_value = <105>;

		oplus_spec,fastchg_timeout_time_init = <175370>;
		oplus_spec,voocphy_ibat_over_current = <16000>;
		oplus_spec,voocphy_svooc_cp_max_ibus = <4200>;
		oplus_spec,voocphy_vooc_cp_max_ibus = <4200>;
		oplus_spec,voocphy_cp_max_ibus = <4500>;

		oplus_spec,vooc_little_cold_full_voltage = <4570>;
		oplus_spec,vooc_cool_full_voltage = <4570>;
		oplus_spec,vooc_little_cool_full_voltage = <4570>;
		oplus_spec,vooc_little_cool_high_full_voltage = <4570>;
		oplus_spec,vooc_warm_full_voltage = <4130>;
		oplus_spec,vooc_1time_full_voltage = <4585>;
		oplus_spec,vooc_ntime_full_voltage = <4575>;
		oplus_spec,full_voltage = < /* vol_1time vol_ntime */
					4580 4570 /* 0 ~ 5 */
					4580 4570 /* 5 ~ 12 */
					4580 4570 /* 12 ~ 16 */
					4580 4570 /* 16 ~ 20 */
					4585 4575 /* 20 ~ 35 */
					4580 4570 /* 35 ~ 44 */
					4140 4130 /* 44 ~ 51 */
					>;

		oplus_spec,low_curr_full_t1 = <120>;
		oplus_spec,low_curr_full_t2 = <350>;
		oplus_spec,low_curr_full_t3 = <430>;
		svooc_batt_sys_curve = <0 1 0 1 0 0 0	// 4000mA
					1 1 1 1 0 0 0	// 4604mV
					0 0 1 1 0 1 0	// 2600mA
					1 1 1 1 0 0 0	// 4604mV
					0 0 0 1 0 1 1	// 1100mA
					1 1 1 1 0 0 0>;	// 4604mV

		vooc_batt_sys_curve =  <0 1 0 1 0 0 0	// 4000mA
					1 1 1 1 0 0 0	// 4604mV
					0 0 1 1 0 1 0	// 2600mA
					1 1 1 1 0 0 0	// 4604mV
					0 0 0 1 0 1 1	// 1100mA
					1 1 1 1 0 0 0>;	// 4604mV

		oplus_spec,soc_range = <0 20 35 55 75 85 90>;

		svooc_lcf_strategy {
			oplus,temp_type = <OPLUS_STRATEGY_USE_SHELL_TEMP>;
			oplus,temp_range = <0 50 120 160 210 380 440>;

			strategy_temp_range_curves {
				strategy_temp_range_t0 =	<1250 4570 0
								 1200 4560 0
								 1150 4550 0
								 1100 4540 0
								 1050 4530 1>;
				strategy_temp_range_t1 =	<1350 4570 0
								 1300 4565 0
								 1250 4550 0
								 1150 4540 0
								 1050 4530 1>;
				strategy_temp_range_t2 =	<2050 4570 0
								 2000 4565 0
								 1900 4550 0
								 1800 4540 0
								 1650 4530 1>;
				strategy_temp_range_t3 =	<2600 4560 0
								 2400 4550 0
								 2000 4542 0
								 1800 4530 0
								 1500 4510 1>;
				strategy_temp_range_t4 =	<2600 4560 0
								 2400 4550 0
								 2000 4542 0
								 1800 4530 0
								 1500 4510 1>;
				strategy_temp_range_t5 =	<3100 4550 0
								 2800 4536 0
								 2400 4524 0
								 2000 4509 0
								 1500 4492 1>;
			};
		};

		svooc_charge_strategy {
			strategy_soc_0_to_50 {  /* 0 ~ 20 */
				strategy_temp_little_cold =	<4150 39 0 0 0
								 4150 35 0 0 0
								 4150 30 0 0 0
								 4510 25 0 0 0
								 4510 20 0 0 0
								 4560 18 0 0 0
								 4560 15 0 0 0
								 4570 10 1 0 0>;
				strategy_temp_cool =		<4150 49 0 0 0
								 4150 45 0 0 0
								 4150 40 0 0 0
								 4510 39 0 0 0
								 4510 35 0 0 0
								 4510 30 0 0 0
								 4560 25 0 0 0
								 4560 20 0 0 0
								 4560 15 0 0 0
								 4570 10 1 0 0>;
				strategy_temp_little_cool =	<4150 73 0 120 0
								 4150 61 0 120 0
								 4510 58 0 360 0
								 4510 50 0 840 0
								 4560 45 0 0 0
								 4560 40 0 0 0
								 4560 35 0 0 0
								 4560 30 0 0 0
								 4560 25 0 0 0
								 4560 20 0 0 0
								 4560 15 0 0 0
								 4565 11 1 0 0>;
				strategy_temp_little_cool_high = <4280 73 0 120 0
								 4510 62 0 120 0
								 4510 50 0 840 0
								 4560 45 0 0 0
								 4560 40 0 0 0
								 4560 35 0 0 0
								 4560 30 0 0 0
								 4560 25 0 0 0
								 4560 20 0 0 0
								 4560 15 0 0 0
								 4565 14 0 0 0
								 4550 10 1 0 0>;
				strategy_temp_normal_low =	<4280 73 0 120 0
								 4510 62 0 120 0
								 4510 50 0 1200 0
								 4560 45 0 0 0
								 4560 40 0 0 0
								 4560 35 0 0 0
								 4560 30 0 0 0
								 4560 25 0 0 0
								 4560 20 0 0 0
								 4560 15 0 0 0
								 4565 14 0 0 0
								 4550 10 1 0 0>;
				strategy_temp_normal_high =	<4280 73 0 60 0
								 4510 62 0 180 0
								 4510 50 0 1200 0
								 4560 45 0 0 0
								 4560 40 0 0 0
								 4560 35 0 0 0
								 4560 30 0 0 0
								 4560 25 0 0 0
								 4560 20 0 0 0
								 4565 16 0 0 0
								 4524 10 1 0 0>;
				strategy_temp_warm =		<4120 18 0 0 0
								 4120 15 0 0 0
								 4130 10 1 0 0>;
			};

			strategy_soc_0_to_50_mid { /* 21 ~ 35 */
				strategy_temp_little_cold =	<4150 39 0 0 0
								 4150 35 0 0 0
								 4150 30 0 0 0
								 4510 25 0 0 0
								 4510 20 0 0 0
								 4560 18 0 0 0
								 4560 15 0 0 0
								 4570 10 1 0 0>;
				strategy_temp_cool =		<4150 49 0 0 0
								 4150 45 0 0 0
								 4150 40 0 0 0
								 4510 39 0 0 0
								 4510 35 0 0 0
								 4510 30 0 0 0
								 4560 25 0 0 0
								 4560 20 0 0 0
								 4560 15 0 0 0
								 4570 10 1 0 0>;
				strategy_temp_little_cool =	<4150 73 0 120 0
								 4150 61 0 120 0
								 4510 58 0 360 0
								 4510 50 0 840 0
								 4560 45 0 0 0
								 4560 40 0 0 0
								 4560 35 0 0 0
								 4560 30 0 0 0
								 4560 25 0 0 0
								 4560 20 0 0 0
								 4560 15 0 0 0
								 4565 11 1 0 0>;
				strategy_temp_little_cool_high = <4280 73 0 120 0
								 4510 62 0 120 0
								 4510 50 0 1200 0
								 4560 45 0 0 0
								 4560 40 0 0 0
								 4560 35 0 0 0
								 4560 30 0 0 0
								 4560 25 0 0 0
								 4560 20 0 0 0
								 4560 15 0 0 0
								 4565 14 0 0 0
								 4550 10 1 0 0>;
				strategy_temp_normal_low =	<4280 73 0 120 0
								 4510 62 0 120 0
								 4510 50 0 1200 0
								 4560 45 0 0 0
								 4560 40 0 0 0
								 4560 35 0 0 0
								 4560 30 0 0 0
								 4560 25 0 0 0
								 4560 20 0 0 0
								 4560 15 0 0 0
								 4565 14 0 0 0
								 4550 10 1 0 0>;
				strategy_temp_normal_high =	<4280 73 0 60 0
								 4510 62 0 180 0
								 4510 50 0 1200 0
								 4560 45 0 0 0
								 4560 40 0 0 0
								 4560 35 0 0 0
								 4560 30 0 0 0
								 4560 25 0 0 0
								 4560 20 0 0 0
								 4565 16 0 0 0
								 4524 10 1 0 0>;
				strategy_temp_warm =		<4120 18 0 0 0
								 4120 15 0 0 0
								 4130 10 1 0 0>;
			};

			strategy_soc_0_to_50_high { /* 36 ~ 55 */
				strategy_temp_little_cold =	<4510 20 0 0 0
								 4560 18 0 0 0
								 4560 15 0 0 0
								 4570 10 1 0 0>;
				strategy_temp_cool =		<4560 25 0 0 0
								 4560 20 0 0 0
								 4560 15 0 0 0
								 4570 10 1 0 0>;
				strategy_temp_little_cool =	<4560 40 0 0 0
								 4560 35 0 0 0
								 4560 30 0 0 0
								 4560 25 0 0 0
								 4560 20 0 0 0
								 4560 15 0 0 0
								 4565 11 1 0 0>;
				strategy_temp_little_cool_high = <4560 40 0 0 0
								 4560 35 0 0 0
								 4560 30 0 0 0
								 4560 25 0 0 0
								 4560 20 0 0 0
								 4560 15 0 0 0
								 4565 14 0 0 0
								 4550 10 1 0 0>;
				strategy_temp_normal_low =	<4280 73 0 120 0
								 4510 62 0 120 0
								 4510 50 0 1200 0
								 4560 45 0 0 0
								 4560 40 0 0 0
								 4560 35 0 0 0
								 4560 30 0 0 0
								 4560 25 0 0 0
								 4560 20 0 0 0
								 4560 15 0 0 0
								 4565 14 0 0 0
								 4550 10 1 0 0>;
				strategy_temp_normal_high =	<4280 73 0 60 0
								 4510 62 0 180 0
								 4510 50 0 1200 0
								 4560 45 0 0 0
								 4560 40 0 0 0
								 4560 35 0 0 0
								 4560 30 0 0 0
								 4560 25 0 0 0
								 4560 20 0 0 0
								 4565 16 0 0 0
								 4524 10 1 0 0>;
				strategy_temp_warm =		<4120 18 0 0 0
								 4120 15 0 0 0
								 4130 10 1 0 0>;
			};

			strategy_soc_50_to_75 { /* 56 ~ 75 */
				strategy_temp_little_cold =	<4560 15 0 0 0
								 4570 10 1 0 0>;
				strategy_temp_cool =		<4560 15 0 0 0
								 4570 10 1 0 0>;
				strategy_temp_little_cool =	<4560 20 0 0 0
								 4560 15 0 0 0
								 4565 11 1 0 0>;
				strategy_temp_little_cool_high = <4560 20 0 0 0
								 4560 15 0 0 0
								 4565 14 0 0 0
								 4550 10 1 0 0>;
				strategy_temp_normal_low =	<4560 25 0 0 0
								 4560 20 0 0 0
								 4560 15 0 0 0
								 4565 14 0 0 0
								 4550 10 1 0 0>;
				strategy_temp_normal_high =	<4560 30 0 0 0
								 4560 25 0 0 0
								 4560 20 0 0 0
								 4565 16 0 0 0
								 4524 10 1 0 0>;
				strategy_temp_warm =		<4130 10 1 0 0>;
			};

			strategy_soc_75_to_85 { /* 76 ~ 85 */
				strategy_temp_little_cold =	<4570 10 1 0 0>;
				strategy_temp_cool =		<4570 10 1 0 0>;
				strategy_temp_little_cool =	<4560 15 0 0 0
								 4565 11 1 0 0>;
				strategy_temp_little_cool_high = <4560 15 0 0 0
								 4565 14 0 0 0
								 4550 10 1 0 0>;
				strategy_temp_normal_low =	<4560 15 0 0 0
								 4565 14 0 0 0
								 4550 10 1 0 0>;
				strategy_temp_normal_high =	<4560 20 0 0 0
								 4565 16 0 0 0
								 4524 10 1 0 0>;
				strategy_temp_warm =		<4130 10 1 0 0>;
			};

			strategy_soc_85_to_90 { /* 86 ~ 90 */
				strategy_temp_little_cold =	<4570 10 1 0 0>;
				strategy_temp_cool =		<4570 10 1 0 0>;
				strategy_temp_little_cool =	<4565 11 1 0 0>;
				strategy_temp_little_cool_high = <4565 14 0 0 0
								 4550 10 1 0 0>;
				strategy_temp_normal_low =	<4565 14 0 0 0
								 4550 10 1 0 0>;
				strategy_temp_normal_high =	<4565 16 0 0 0
								 4524 10 1 0 0>;
				strategy_temp_warm =		<4130 10 1 0 0>;
			};
		};

		vooc_charge_strategy {
			strategy_soc_0_to_50 { /* 0 ~ 20 */
				strategy_temp_little_cold =	<4150 60 0 0 0
								 4510 50 0 0 0
								 4510 40 0 0 0
								 4560 36 0 0 0
								 4560 30 0 0 0
								 4570 20 1 0 0>;
				strategy_temp_cool =		<4510 60 0 0 0
								 4560 50 0 0 0
								 4560 40 0 0 0
								 4560 30 0 0 0
								 4570 20 1 0 0>;
				strategy_temp_little_cool =	<4560 60 0 0 0
								 4560 50 0 0 0
								 4560 40 0 0 0
								 4560 30 0 0 0
								 4565 22 1 0 0>;
				strategy_temp_little_cool_high = <4560 60 0 0 0
								 4560 50 0 0 0
								 4560 40 0 0 0
								 4560 30 0 0 0
								 4565 28 0 0 0
								 4550 20 1 0 0>;
				strategy_temp_normal_low =	<4560 60 0 0 0
								 4560 50 0 0 0
								 4560 40 0 0 0
								 4560 30 0 0 0
								 4565 28 0 0 0
								 4550 20 1 0 0>;
				strategy_temp_normal_high =	<4560 60 0 0 0
								 4560 50 0 0 0
								 4560 40 0 0 0
								 4565 32 0 0 0
								 4524 20 1 0 0>;
				strategy_temp_warm =		<4120 36 0 0 0
								 4120 30 0 0 0
								 4130 20 1 0 0>;
			};

			strategy_soc_0_to_50_mid { /* 21 ~ 35 */
				strategy_temp_little_cold =	<4150 60 0 0 0
								 4510 50 0 0 0
								 4510 40 0 0 0
								 4560 36 0 0 0
								 4560 30 0 0 0
								 4570 20 1 0 0>;
				strategy_temp_cool =		<4510 60 0 0 0
								 4560 50 0 0 0
								 4560 40 0 0 0
								 4560 30 0 0 0
								 4570 20 1 0 0>;
				strategy_temp_little_cool =	<4560 60 0 0 0
								 4560 50 0 0 0
								 4560 40 0 0 0
								 4560 30 0 0 0
								 4565 22 1 0 0>;
				strategy_temp_little_cool_high = <4560 60 0 0 0
								 4560 50 0 0 0
								 4560 40 0 0 0
								 4560 30 0 0 0
								 4565 28 0 0 0
								 4550 20 1 0 0>;
				strategy_temp_normal_low =	<4560 60 0 0 0
								 4560 50 0 0 0
								 4560 40 0 0 0
								 4560 30 0 0 0
								 4565 28 0 0 0
								 4550 20 1 0 0>;
				strategy_temp_normal_high =	<4560 60 0 0 0
								 4560 50 0 0 0
								 4560 40 0 0 0
								 4565 32 0 0 0
								 4524 20 1 0 0>;
				strategy_temp_warm =		<4120 36 0 0 0
								 4120 30 0 0 0
								 4130 20 1 0 0>;
			};

			strategy_soc_0_to_50_high { /* 36 ~ 55 */
				strategy_temp_little_cold =	<4510 40 0 0 0
								 4560 36 0 0 0
								 4560 30 0 0 0
								 4570 20 1 0 0>;
				strategy_temp_cool =		<4560 50 0 0 0
								 4560 40 0 0 0
								 4560 30 0 0 0
								 4570 20 1 0 0>;
				strategy_temp_little_cool =	<4560 60 0 0 0
								 4560 50 0 0 0
								 4560 40 0 0 0
								 4560 30 0 0 0
								 4565 22 1 0 0>;
				strategy_temp_little_cool_high = <4560 60 0 0 0
								 4560 50 0 0 0
								 4560 40 0 0 0
								 4560 30 0 0 0
								 4565 28 0 0 0
								 4550 20 1 0 0>;
				strategy_temp_normal_low =	<4560 60 0 0 0
								 4560 50 0 0 0
								 4560 40 0 0 0
								 4560 30 0 0 0
								 4565 28 0 0 0
								 4550 20 1 0 0>;
				strategy_temp_normal_high =	<4560 60 0 0 0
								 4560 50 0 0 0
								 4560 40 0 0 0
								 4565 32 0 0 0
								 4524 20 1 0 0>;
				strategy_temp_warm =		<4120 36 0 0 0
								 4120 30 0 0 0
								 4130 20 1 0 0>;
			};

			strategy_soc_50_to_75 { /* 56 ~ 75 */
				strategy_temp_little_cold =	<4560 30 0 0 0
								 4570 20 1 0 0>;
				strategy_temp_cool =		<4560 30 0 0 0
								 4570 20 1 0 0>;
				strategy_temp_little_cool =	<4560 40 0 0 0
								 4560 30 0 0 0
								 4565 22 1 0 0>;
				strategy_temp_little_cool_high = <4560 40 0 0 0
								 4560 30 0 0 0
								 4565 28 0 0 0
								 4550 20 1 0 0>;
				strategy_temp_normal_low =	<4560 50 0 0 0
								 4560 40 0 0 0
								 4560 30 0 0 0
								 4565 28 0 0 0
								 4550 20 1 0 0>;
				strategy_temp_normal_high =	<4560 60 0 0 0
								 4560 50 0 0 0
								 4560 40 0 0 0
								 4565 32 0 0 0
								 4524 20 1 0 0>;
				strategy_temp_warm =		<4130 20 1 0 0>;
			};

			strategy_soc_75_to_85 { /* 76 ~ 85 */
				strategy_temp_little_cold =	<4570 20 1 0 0>;
				strategy_temp_cool =		<4570 20 1 0 0>;
				strategy_temp_little_cool =	<4560 30 0 0 0
								 4565 22 1 0 0>;
				strategy_temp_little_cool_high = <4560 30 0 0 0
								 4565 28 0 0 0
								 4550 20 1 0 0>;
				strategy_temp_normal_low =	<4560 30 0 0 0
								 4565 28 0 0 0
								 4550 20 1 0 0>;
				strategy_temp_normal_high =	<4560 40 0 0 0
								 4565 32 0 0 0
								 4524 20 1 0 0>;
				strategy_temp_warm =		<4130 20 1 0 0>;
			};

			strategy_soc_85_to_90 { /* 86 ~ 90 */
				strategy_temp_little_cold =	<4570 20 1 0 0>;
				strategy_temp_cool =		<4570 20 1 0 0>;
				strategy_temp_little_cool =	<4565 22 1 0 0>;
				strategy_temp_little_cool_high = <4565 28 0 0 0
								 4550 20 1 0 0>;
				strategy_temp_normal_low =	<4565 28 0 0 0
								 4550 20 1 0 0>;
				strategy_temp_normal_high =	<4565 32 0 0 0
								 4524 20 1 0 0>;
				strategy_temp_warm =		<4130 20 1 0 0>;
			};
		};

		oplus_sc8547_cp: oplus,sc8547_cp {
			oplus,ic_type = <OPLUS_CHG_IC_CP>;
			oplus,ic_index = <0>;
			oplus,ic_func_group = <&sc8547_cp_groups>;
		};
	};
};

&qupv3_se8_i2c {
	status = "okay";
	clock-frequency = <400000>;
	oplus_sc8547_slave: sc8547-charger-slave@6A{
		status = "okay";
		compatible = "oplus,sc8547d";
		reg = <0x6A>;

		ocp_reg = <0xe>;
		ovp_reg = <0x36>;
		oplus,use_slave_cp;
		vbus_ovp_reg = /bits/ 8 <0x5A>;

		oplus,irq_gpio = <&tlmm 128 0x00>;
		pinctrl-names = "charging_inter_active", "charging_inter_sleep";
		pinctrl-0 = <&slave_charging_inter_active>;
		pinctrl-1 = <&slave_charging_inter_sleep>;

		oplus_sc8547_slave_cp: oplus,sc8547_slave_cp {
			oplus,ic_type = <OPLUS_CHG_IC_CP>;
			oplus,ic_index = <1>;
		};
	};
};


